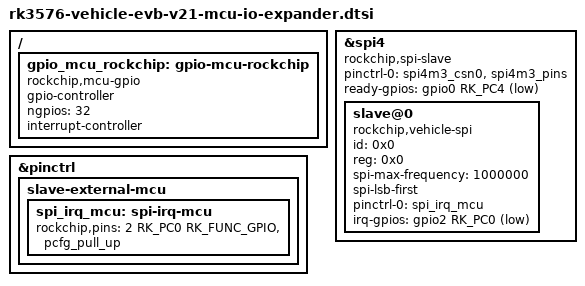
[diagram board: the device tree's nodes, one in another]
// SPDX-License-Identifier: (GPL-2.0+ OR MIT)
/*
 * Copyright (c) 2023 Rockchip Electronics Co., Ltd.
 *
 */

/ {
	gpio_mcu_rockchip: gpio-mcu-rockchip {
		compatible = "rockchip,mcu-gpio";
		gpio-controller;
		#gpio-cells = <2>;
		ngpios = <32>;
		interrupt-controller;
		#interrupt-cells = <2>;
		status = "okay";
	};
};

&spi4 {
	compatible = "rockchip,spi-slave";
	status = "okay";
	pinctrl-names = "default", "high_speed";
	pinctrl-0 = <&spi4m3_csn0 &spi4m3_pins>;
	ready-gpios = <&gpio0 RK_PC4 GPIO_ACTIVE_LOW>;
	slave@0 {
		compatible = "rockchip,vehicle-spi";
		status = "okay";
		id  = <0x0>;
		reg = <0x0>;
		spi-max-frequency = <1000000>;
		spi-lsb-first;
		pinctrl-names = "default";
		pinctrl-0 = <&spi_irq_mcu>;
		irq-gpios = <&gpio2 RK_PC0 GPIO_ACTIVE_LOW>;
	};
};

&pinctrl {
	slave-external-mcu {
		spi_irq_mcu: spi-irq-mcu {
			rockchip,pins = <2 RK_PC0 RK_FUNC_GPIO &pcfg_pull_up>;
		};
	};
};
